# SKEAZN84 register map
Vendor: Freescale Semiconductor, Inc.; File version: 1.6
CPU: CM0PLUS r0p0, little endian, no MPU, no FPU, 0x2 interrupt priority bits, 0x0 interrupts
Registers are 32-bit, read-write, reset 0x0 unless marked. A register's access mark holds for its fields unless they carry their own. Offsets are from the block's base; [hi:lo] are bit positions; {n}, {i} and the like mark numbered series; 'fields as' and 'values as' point back to an identical list.

## PWT — Pulse Width Timer
Base 0x40033000; register names take the prefix PWT_
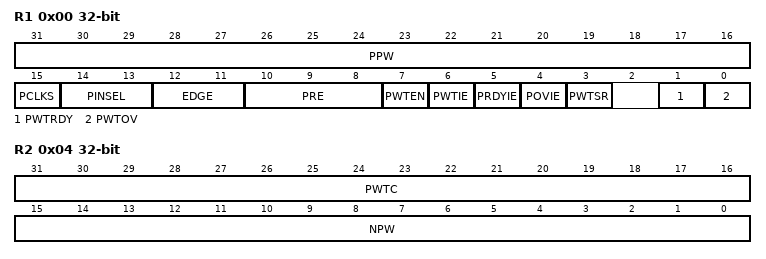
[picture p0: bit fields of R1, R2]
0x00 R1 — Pulse Width Timer Register 1
  [31:16] PPW ro — Positive Pulse Width
  [15] PCLKS — PWT Clock Source Selection
    0=Bus clock is selected as the clock source of PWT counter; 1=Alternative clock is selected as the clock source of PWT counter
  [14:13] PINSEL — PWT Pulse Inputs Selection
    {v}=PWTIN[{v}] (v=0..3)
  [12:11] EDGE — PWT input edge sensitivity
    0=The first falling edge starts the pulse width measurement, upon all the following falling edges, the pulse width is captured; 1=The first rising edge starts the pulse width measurement, upon all the following rising and falling edges, the pulse width is captured; 2=The first falling edge starts the pulse width measurement, upon all the following rising and falling edges, the pulse width is captured; 3=The first rising edge starts the pulse width measurement, upon all the following rising edges, the pulse width is captured
  [10:8] PRE — PWT Clock Pre-scaler(CLKPRE) Setting
    0=Clock divied by 1; 1=Clock divied by 2; 2=Clock divied by 4; 3=Clock divied by 8; 4=Clock divied by 16; 5=Clock divied by 32; 6=Clock divied by 64; 7=Clock divied by 128
  [7] PWTEN — PWT Module Enable
    0=The PWT is disabled; 1=The PWT is enabled
  [6] PWTIE — PWT module interrupt enable
    0=Disables the PWT to generate interrupt; 1=Enables the PWT to generate interrupt
  [5] PRDYIE — PWT pulse width data ready interrupt enable
    0=Disable PWT to generate interrupt when PWTRDY is set; 1=Enable PWT to generate interrupt when PWTRDY is set
  [4] POVIE — PWT counter overflow interrupt enable
    0=Disable PWT to generate interrupt when PWTOV is set; 1=Enable PWT to generate interrupt when PWTOV is set
  [3] PWTSR — PWT Soft Reset
    0=No action taken; 1=Writing 1 to this bit will perform soft reset to PWT
  [1] PWTRDY — PWT pulse width valid
    0=PWT pulse width register(s) is not up-to-date; 1=PWT pulse width register(s) has been updated
  [0] PWTOV — PWT counter overflow
    0=PWT counter no overflow; 1=PWT counter run from 0xFFFF to 0x0000
0x04 R2 ro — Pulse Width Timer Register 2
  [31:16] PWTC — PWT counter.It is suggested to use half-word(16bit) or word(32bit) to read out this value.
  [15:0] NPW — Negative Pulse Width. It is suggested to use half-word(16bit) or word(32bit) to read out this value.

## PIT — Periodic Interrupt Timer
Base 0x40037000; register names take the prefix PIT_
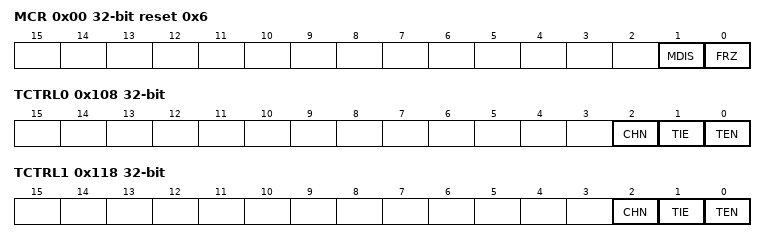
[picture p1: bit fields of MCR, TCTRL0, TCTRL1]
0x00 MCR reset 0x6 — PIT Module Control Register
  [1] MDIS — Module Disable - (PIT section)
    0=Clock for standard PIT timers is enabled; 1=Clock for standard PIT timers is disabled
  [0] FRZ — Freeze
    0=Timers continue to run in Debug mode; 1=Timers are stopped in Debug mode
0x100 LDVAL0 — Timer Load Value Register
  [31:0] TSV — Timer Start Value
0x104 CVAL0 ro — Current Timer Value Register
  [31:0] TVL — Current Timer Value
0x108 TCTRL0 — Timer Control Register
  [2] CHN — Chain Mode
    0=Timer is not chained; 1=Timer is chained to previous timer. For example, for Channel 2, if this field is set, Timer 2 is chained to Timer 1.
  [1] TIE — Timer Interrupt Enable
    0=Interrupt requests from Timer n are disabled; 1=Interrupt will be requested whenever TIF is set
  [0] TEN — Timer Enable
    0=Timer n is disabled; 1=Timer n is enabled
0x10C TFLG0 — Timer Flag Register
  [0] TIF — Timer Interrupt Flag
    0=Timeout has not yet occurred; 1=Timeout has occurred
0x110 LDVAL1 — Timer Load Value Register
  [31:0] TSV — Timer Start Value
0x114 CVAL1 ro — Current Timer Value Register
  [31:0] TVL — Current Timer Value
0x118 TCTRL1 — Timer Control Register
  fields as TCTRL0
0x11C TFLG1 — Timer Flag Register
  fields as TFLG0
